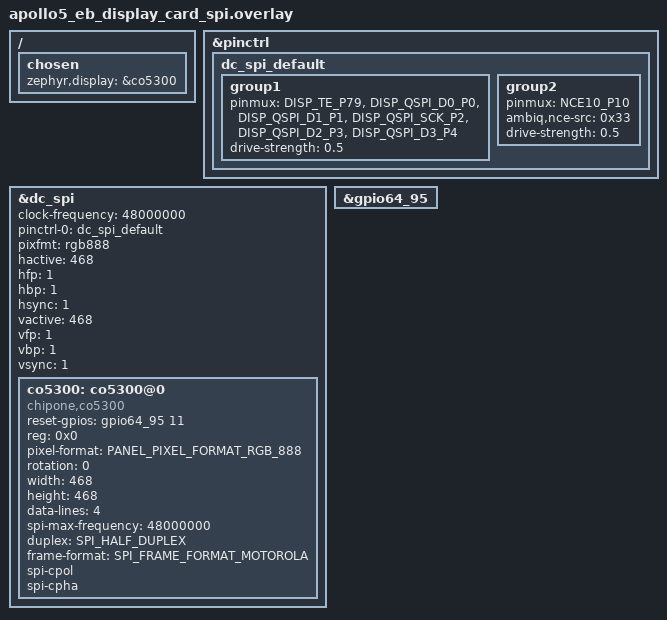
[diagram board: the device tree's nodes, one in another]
/*
 * Copyright (c) 2025 Ambiq Micro Inc.
 *
 * SPDX-License-Identifier: Apache-2.0
 */
#include <apollo510L/ambiq-apollo510L-pinmux.h>
#include <zephyr/dt-bindings/spi/spi.h>
#include <zephyr/dt-bindings/display/panel.h>

/ {
	chosen {
		zephyr,display = &co5300;
	};
};

&pinctrl {
	/* QSPI pinctrl */
	dc_spi_default: dc_spi_default {
		group1 {
			pinmux = <DISP_TE_P79>,
				<DISP_QSPI_D0_P0>,
				<DISP_QSPI_D1_P1>,
				<DISP_QSPI_SCK_P2>,
				<DISP_QSPI_D2_P3>,
				<DISP_QSPI_D3_P4>;
			drive-strength = "0.5";
		};
		group2 {
			pinmux = <NCE10_P10>;
			ambiq,nce-src = <0x33>;
			drive-strength = "0.5";
		};
	};
	/* SPI/DSPI pinctrl,co5300 couldn't support SPI.
	 * dc_spi_default: dc_spi_default {
	 *	group1 {
	 *		pinmux = <DISP_TE_P79>,
	 *			<DISP_SPI_SD_P0>,
	 *			<DISP_SPI_DCX_P1>,
	 *			<DISP_SPI_SCK_P2>,
	 *		drive-strength = "0.5";
	 *	};
	 *	group2 {
	 *		pinmux = <NCE10_P10>;
	 *		ambiq,nce-src = <0x32>;
	 *		drive-strength = "0.5";
	 *	};
	 *};
	 */
};

&dc_spi {
	status = "okay";
	/*clock-frequency should not be greater than spi-max-frequency*/
	clock-frequency = <48000000>;
	/*disp-te;*/
	pinctrl-0 = <&dc_spi_default>;
	pinctrl-names = "default";
	pixfmt = "rgb888";
	hactive = <468>;	/*its value depends on display size*/
	hfp = <1>;	/*Please use this recommended value.*/
	hbp = <1>;	/*Please use this recommended value.*/
	hsync = <1>;	/*Please use this recommended value.*/
	vactive = <468>;	/*its value depends on display size*/
	vfp = <1>;	/*Please use this recommended value.*/
	vbp = <1>;	/*Please use this recommended value.*/
	vsync = <1>;	/*Please use this recommended value.*/

	co5300: co5300@0 {
		status = "okay";
		compatible = "chipone,co5300";
		reset-gpios = <&gpio64_95 11 (GPIO_PULL_UP)>;
		reg = <0x0>;
		pixel-format = <PANEL_PIXEL_FORMAT_RGB_888>;
		rotation = <0>;
		width = <468>;	/*Its value should be an integer multiple of 4.*/
		height = <468>;

		data-lines = <4>;
		spi-max-frequency = <48000000>;
		duplex = <SPI_HALF_DUPLEX>;
		frame-format = <SPI_FRAME_FORMAT_MOTOROLA>;
		spi-cpol;
		spi-cpha;
		/*spi-hold-cs;*/
	};
};

&gpio64_95 {
	status = "okay";
};
